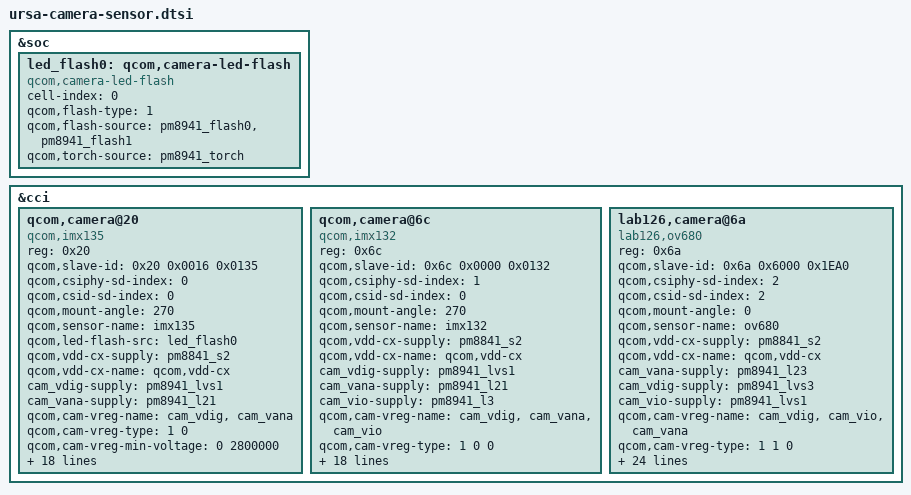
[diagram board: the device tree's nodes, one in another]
/*
 * Copyright (c) 2012-2013, The Linux Foundation. All rights reserved.
 *
 * This program is free software; you can redistribute it and/or modify
 * it under the terms of the GNU General Public License version 2 and
 * only version 2 as published by the Free Software Foundation.
 *
 * This program is distributed in the hope that it will be useful,
 * but WITHOUT ANY WARRANTY; without even the implied warranty of
 * MERCHANTABILITY or FITNESS FOR A PARTICULAR PURPOSE.  See the
 * GNU General Public License for more details.
 */
&soc {
	led_flash0: qcom,camera-led-flash {
		cell-index = <0>;
		compatible = "qcom,camera-led-flash";
		qcom,flash-type = <1>;
		qcom,flash-source = <&pm8941_flash0 &pm8941_flash1>;
		qcom,torch-source = <&pm8941_torch>;
	};
};

&cci {
	qcom,camera@20 {
		compatible = "qcom,imx135";
		reg = <0x20>;
		qcom,slave-id = <0x20 0x0016 0x0135>;
		qcom,csiphy-sd-index = <0>;
		qcom,csid-sd-index = <0>;
		qcom,mount-angle = <270>;
		qcom,sensor-name = "imx135";
		qcom,led-flash-src = <&led_flash0>;
		qcom,vdd-cx-supply = <&pm8841_s2>;
		qcom,vdd-cx-name = "qcom,vdd-cx";
		cam_vdig-supply = <&pm8941_lvs1>;
		cam_vana-supply = <&pm8941_l21>;
		qcom,cam-vreg-name = "cam_vdig", "cam_vana";
		qcom,cam-vreg-type = <1 0>;
		qcom,cam-vreg-min-voltage = <0 2800000>;
		qcom,cam-vreg-max-voltage = <0 2800000>;
		qcom,cam-vreg-op-mode = <0 85000>;
		qcom,gpio-no-mux = <0>;
		gpios = <&msmgpio 15 0>,
			<&msmgpio 89 0>;
		qcom,gpio-reset = <1>;
		qcom,gpio-req-tbl-num = <0 1>;
		qcom,gpio-req-tbl-flags = <1 0 0>;
		qcom,gpio-req-tbl-label = "CAMIF_MCLK0_MSM",
					  "CAM_RFC_PWDN_N";
		qcom,gpio-set-tbl-num = <1 1>;
		qcom,gpio-set-tbl-flags = <0 2>;
		qcom,gpio-set-tbl-delay = <1000 30000>;
		qcom,csi-lane-assign = <0x4230>;
		qcom,csi-lane-mask = <0x1F>;
		qcom,sensor-position = <0>;
		qcom,sensor-mode = <0>;
	        qcom,sensor-type = <0>;
		qcom,cci-master = <0>;
		status = "ok";
	};

	qcom,camera@6c {
		compatible = "qcom,imx132";
		reg = <0x6c>;
		qcom,slave-id = <0x6c 0x0000 0x0132>;
		qcom,csiphy-sd-index = <1>;
		qcom,csid-sd-index = <0>;
		qcom,mount-angle = <270>;
		qcom,sensor-name = "imx132";
		qcom,vdd-cx-supply = <&pm8841_s2>;
		qcom,vdd-cx-name = "qcom,vdd-cx";
		cam_vdig-supply = <&pm8941_lvs1>;
		cam_vana-supply = <&pm8941_l21>;
		cam_vio-supply = <&pm8941_l3>;
		qcom,cam-vreg-name = "cam_vdig", "cam_vana", "cam_vio";
		qcom,cam-vreg-type = <1 0 0>;
		qcom,cam-vreg-min-voltage = <0 2800000 1225000>;
		qcom,cam-vreg-max-voltage = <0 2800000 1225000>;
		qcom,cam-vreg-op-mode = <0 85000 85000>;
		qcom,gpio-no-mux = <0>;
		gpios = <&msmgpio 15 0>,
			<&msmgpio 31 0>;
		qcom,gpio-reset = <1>;
		qcom,gpio-req-tbl-num = <0 1>;
		qcom,gpio-req-tbl-flags = <1 0> ;
		qcom,gpio-req-tbl-label = "CAM_MCLK0_MSM",
						 "CAM_FFC_PWDN_N";
		qcom,gpio-set-tbl-num = <1 1>;
		qcom,gpio-set-tbl-flags = <0 2>;
		qcom,gpio-set-tbl-delay = <1000 30000>;
		qcom,csi-lane-assign = <0x4320>;
		qcom,csi-lane-mask = <0x7>;
		qcom,sensor-position = <1>;
		qcom,sensor-mode = <1>;
		qcom,cci-master = <0>;
		status = "ok";
	};
	lab126,camera@6a {
		compatible = "lab126,ov680";
		reg = <0x6a>;
		qcom,slave-id = <0x6a 0x6000 0x1EA0>;
		qcom,csiphy-sd-index = <2>;
		qcom,csid-sd-index = <2>;
		qcom,mount-angle = <0>;
		qcom,sensor-name = "ov680";
		qcom,vdd-cx-supply = <&pm8841_s2>;
		qcom,vdd-cx-name = "qcom,vdd-cx";
		cam_vana-supply = <&pm8941_l23>;
		cam_vdig-supply = <&pm8941_lvs3>;
		cam_vio-supply  = <&pm8941_lvs1>;
		qcom,cam-vreg-name = "cam_vdig", "cam_vio", "cam_vana";
		qcom,cam-vreg-type = <1 1 0 >;
		qcom,cam-vreg-min-voltage = < 0 0 2800000 >;
		qcom,cam-vreg-max-voltage = <0 0 2800000>;
		qcom,cam-vreg-op-mode = <0 0 80000>;
		qcom,gpio-no-mux = <0>;
		gpios = <&msmgpio 16 0>,
			<&msmgpio 26 0>,
			<&msmgpio 23 0>,
			<&msmgpio 56 0>,
			<&msmgpio 18 0>;
		interrupt-parent = <&msmgpio>;
		interrupts = <18 0>;
		lab126,gpio-cmd-rdy-irq-num = <4>;
		qcom,gpio-reset = <1>;
		qcom,gpio-standby = <2>;
		qcom,gpio-req-tbl-num = <0 1 2 3>;
		qcom,gpio-req-tbl-flags = <1 0 0 0>;
		qcom,gpio-req-tbl-label = "CAM_4CC_MCLK1",
						  "CAM_4CC_XPWDN",
				          "CAM_4CC_RST_N",
				          "CAM_4CC_LED_QUAD";
		qcom,gpio-set-tbl-num = <1 1 2 2>;
		qcom,gpio-set-tbl-flags = <0 2 0 2>;
		qcom,gpio-set-tbl-delay = <0 0 1000 4000>;
		qcom,csi-lane-assign = <0x4320>;
		qcom,csi-lane-mask = <0x7>;
		qcom,sensor-position = <2>;
		qcom,sensor-mode = <1>;
		qcom,cci-master=<0>;
		status = "ok";
	};

};
